# RK3399-AP register map
File version: 1
CPU: CA7 r0p1, little endian, MPU, FPU, I-cache, D-cache, VTOR, 4 interrupt priority bits, 0 interrupts
Registers are 32-bit, read-write, reset 0x0 unless marked. A register's access mark holds for its fields unless they carry their own. Offsets are from the block's base; [hi:lo] are bit positions; {n}, {i} and the like mark numbered series; <NAME> marks a mode.

## I2C0
Base 0xFF3C0000
Same registers: I2C1 0xFF110000, I2C2 0xFF120000, I2C3 0xFF130000, I2C5 0xFF140000, I2C6 0xFF150000, I2C7 0xFF160000, I2C4 0xFF3D0000, I2C8 0xFF3E0000
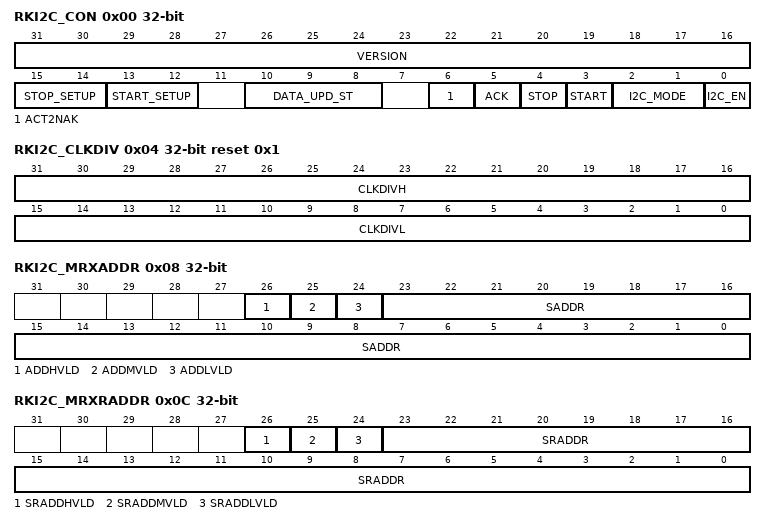
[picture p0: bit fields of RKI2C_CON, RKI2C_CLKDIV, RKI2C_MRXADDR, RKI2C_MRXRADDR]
0x00 RKI2C_CON access per field — control register
  [31:16] VERSION ro — rki2c version version information
  [15:14] STOP_SETUP rw — staop setup config TSU;sto = (stop_setup + 1) * T(SCL_HIGH) + Tclk_i2c
  [13:12] START_SETUP rw — start setup config TSU;sta = (start_setup + 1) * T(SCL_HIGH) + Tclk_i2c THD;sta = (start_setup + 2) * T(SCL_HIGH) - Tclk_i2c
  [10:8] DATA_UPD_ST rw — SDA update point config Used to config sda change state when scl is low, used to adjust setup/hold time 4\'bn:Thold = (n + 1) * Tclk_i2c Note: 0 <= n <= 5
  [6] ACT2NAK rw — operation when NAK handshake is received 1\'b0: ignored 1\'b1: stop transaction
  [5] ACK rw — last byte acknowledge control in master receive mode 1\'b0: ACK 1\'b1: NAK
  [4] STOP rw — stop enable stop enable, when this bit is written to 1, I2C will generate stop signal.
  [3] START rw — start enable start enable, when this bit is written to 1, I2C will generate start signal.
  [2:1] I2C_MODE rw — i2c mode select 2\'b00: transmit only 2\'b01: transmit address (device + register address) --> restart - -> transmit address -> receive only 2\'b10: receive only 2\'b11: transmit address (device + register address, write/read bit is 1) --> restart --> transmit address (device address) --> receive data
  [0] I2C_EN rw — i2c module enable 1\'b0:not enable 1\'b1:enable
0x04 RKI2C_CLKDIV reset 0x1 — clock divider register
  [31:16] CLKDIVH — scl high level clock count T(SCL_HIGH) = Tclk_i2c * (CLKDIVH + 1) * 8
  [15:0] CLKDIVL — scl low level clock count T(SCL_LOW) = Tclk_i2c * (CLKDIVL + 1) * 8
0x08 RKI2C_MRXADDR — the slave address accessed for master rx mode
  [26] ADDHVLD — address high byte valid 1\'b0:invalid 1\'b1:valid
  [25] ADDMVLD — address middle byte valid 1\'b0:invalid 1\'b1:valid
  [24] ADDLVLD — address low byte valid 1\'b0:invalid 1\'b1:valid
  [23:0] SADDR — master address register the lowest bit indicate write or read 24 bits address register
0x0C RKI2C_MRXRADDR — the slave register address accessed for master rx mode
  [26] SRADDHVLD — address high byte valid 1\'b0:invalid 1\'b1:valid
  [25] SRADDMVLD — address middle byte valid 1\'b0:invalid 1\'b1:valid
  [24] SRADDLVLD — address low byte valid 1\'b0:invalid 1\'b1:valid
  [23:0] SRADDR — slave register address accessed 24 bits register address
0x10 RKI2C_MTXCNT — master transmit count
  [5:0] MTXCNT — master transmit count 6 bits counter
0x14 RKI2C_MRXCNT — master rx count
  [5:0] MRXCNT — master rx count 6 bits counter
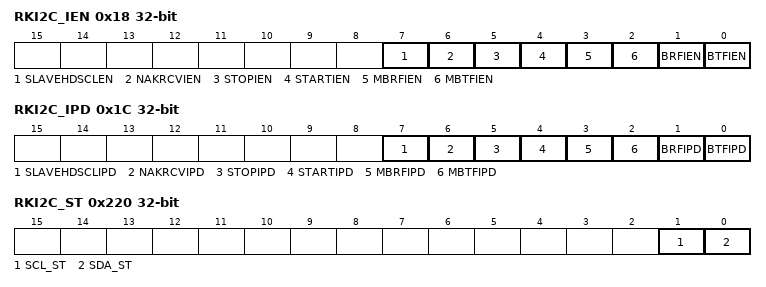
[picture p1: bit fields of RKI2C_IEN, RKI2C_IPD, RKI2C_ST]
0x18 RKI2C_IEN — interrupt enable register
  [7] SLAVEHDSCLEN — slave hold scl interrupt enable 1\'b0:disable 1\'b1:enable
  [6] NAKRCVIEN — NAK handshake received interrupt enable 1\'b0:disable 1\'b1:enable
  [5] STOPIEN — stop operation finished interrupt enable 1\'b0:disable 1\'b1:enable
  [4] STARTIEN — start operation finished interrupt enable 1\'b0:disable 1\'b1:enable
  [3] MBRFIEN — MRXCNT data received finished interrupt enable 1\'b0:disable 1\'b1:enable
  [2] MBTFIEN — MTXCNT data transfer finished interrupt enable 1\'b0:disable 1\'b1:enable
  [1] BRFIEN — byte rx finished interrupt enable 1\'b0:disable 1\'b1:enable
  [0] BTFIEN — byte tx finished interrupt enable 1\'b0:disable 1\'b1:enable
0x1C RKI2C_IPD — interrupt pending register
  [7] SLAVEHDSCLIPD — slave hold scl interrupt pending bit 1\'b0:no interrupt available 1\'b1:slave hold scl interrupt appear, write 1 to clear
  [6] NAKRCVIPD write-1-clears — NAK handshake received interrupt pending bit 1\'b0:no interrupt available 1\'b1:NAK handshake received interrupt appear, write 1 to clear
  [5] STOPIPD write-1-clears — stop operation finished interrupt pending bit 1\'b0:no interrupt available 1\'b1:stop operation finished interrupt appear, write 1 to clear
  [4] STARTIPD write-1-clears — start operation finished interrupt pending bit 1\'b0:no interrupt available 1\'b1:start operation finished interrupt appear, write 1 to clear
  [3] MBRFIPD write-1-clears — MRXCNT data received finished interrupt pending bit 1\'b0:no interrupt available 1\'b1:MRXCNT data received finished interrupt appear, write 1 to clear
  [2] MBTFIPD write-1-clears — MTXCNT data transfer finished interrupt pending bit 1\'b0:no interrupt available 1\'b1:MTXCNT data transfer finished interrupt appear, write 1 to clear
  [1] BRFIPD write-1-clears — byte rx finished interrupt pending bit 1\'b0:no interrupt available 1\'b1:byte rx finished interrupt appear, write 1 to clear
  [0] BTFIPD write-1-clears — byte tx finished interrupt pending bit 1\'b0:no interrupt available 1\'b1:byte tx finished interrupt appear, write 1 to clear
0x20 RKI2C_FCNT ro — finished count
  [5:0] FCNT — finished count the count of data which has been transmitted or received for debug purpose
0x24 RKI2C_SCL_OE_DB reset 0x20 — slave hold debounce configure register
  [7:0] SCL_OE_DB — slave hold scl debounce cycles for debounce (unit: Tclk_i2c)
{0x100+4i} RKI2C_TXDATA{i} (i=0..7) — I2C tx data register n
  [31:0] RKI2C_TXDATA — 32-byte data to transmit
{0x200+4i} RKI2C_RXDATA{i} (i=0..7) ro — I2C rx data register n
  [31:0] RKI2C_RXDATA — 32-byte received data
0x220 RKI2C_ST ro — status debug register
  [1] SCL_ST — scl status 1\'b0: scl status low 1\'b0: scl status high
  [0] SDA_ST — sda status 1\'b0: sda status low 1\'b0: sda status high receive ？
